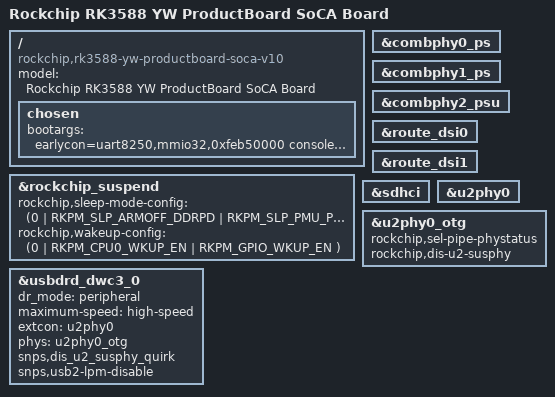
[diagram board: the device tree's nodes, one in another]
// SPDX-License-Identifier: (GPL-2.0+ OR MIT)
/*
 * Copyright (c) 2025 Rockchip Electronics Co., Ltd.
 *
 */

/dts-v1/;

#include "dt-bindings/usb/pd.h"
#include "rk3588m.dtsi"
#include "rk3588-yw-v10.dtsi"
#include "rk3588-rk806-dual.dtsi"
#include "rk3588-android.dtsi"
//#include "rk3588-yw-v10-soca-audio.dtsi"
//#include "rk3588-yw-fastboard-maxim-max96712-dphy0.dtsi"

/ {
	model = "Rockchip RK3588 YW ProductBoard SoCA Board";
	compatible = "rockchip,rk3588-yw-productboard-soca-v10", "rockchip,rk3588";

	chosen: chosen {
		bootargs = "earlycon=uart8250,mmio32,0xfeb50000 console=ttyFIQ0 irqchip.gicv3_pseudo_nmi=0 rcupdate.rcu_expedited=1 rcu_nocbs=all spidev.bufsiz=131072 default_hugepagesz=32M hugepagesz=32M hugepages=16";
	};
};

&combphy0_ps {
	status = "okay";
};

&combphy1_ps {
	status = "okay";
};

&combphy2_psu {
	status = "okay";
};

#if 0
&gmac0 {
	/* Use rgmii-rxid mode to disable rx delay inside Soc */
	phy-mode = "rgmii-rxid";
	clock_in_out = "output";
	snps,reset-gpio = <&gpio3 RK_PB7 GPIO_ACTIVE_LOW>;
	snps,reset-active-low;
	/* Reset time is 20ms, 100ms for rtl8211f */
	snps,reset-delays-us = <0 20000 100000>;
	pinctrl-names = "default";
	pinctrl-0 = <&gmac0_miim
		     &gmac0_tx_bus2
		     &gmac0_rx_bus2
		     &gmac0_rgmii_clk
		     &gmac0_rgmii_bus
		     &phydisb>;
	tx_delay = <0x20>;
	phy-handle = <&rgmii_phy>;
	status = "okay";
};

&i2s0_8ch {
	status = "okay";
	pinctrl-0 = <&i2s0_lrck
		     &i2s0_sclk
		     &i2s0_sdi0
		     &i2s0_sdo0>;
};

&mdio0 {
	rgmii_phy: phy@1 {
		compatible = "ethernet-phy-ieee802.3-c22";
		reg = <0x1>;
		motorcomm,vddio = "1v8";
	};
};
#endif

#if 0
&pcie30phy {
	rockchip,pcie30-phymode = <PHY_MODE_PCIE_AGGREGATION>;
	status = "okay";
};

&pcie3x4 {
	reset-gpios = <&gpio3 RK_PC6 GPIO_ACTIVE_HIGH>;
	//vpcie3v3-supply = <&vcc3v3_pcie30>;
	pinctrl-names = "default";
	pinctrl-0 = <&pcie20x1_0_clkreqn_m1>;
	status = "okay";
};

&pinctrl {
	gmac0 {
		phydisb: phydisb {
			rockchip,pins = <4 RK_PB5 RK_FUNC_GPIO &pcfg_output_high>;
		};
	};

/*
	vcc5v0-buck {
		vcc5v0_buck_en: vcc5v0-buck-en {
			rockchip,pins = <0 RK_PC2 RK_FUNC_GPIO &pcfg_pull_none>;
		};
	};
*/

	pcie {
		pcie20x1_0_clkreqn_m1: pcie20x1-0-clkreqn-m1 {
			rockchip,pins = <3 RK_PC4 RK_FUNC_GPIO &pcfg_output_low>;
		};
	};
};
#endif

&rockchip_suspend {
	rockchip,sleep-mode-config = <
		(0
		| RKPM_SLP_ARMOFF_DDRPD
		| RKPM_SLP_PMU_PMUALIVE_32K
		| RKPM_SLP_PMU_DIS_OSC
		| RKPM_SLP_32K_EXT
		)
	>;
	rockchip,wakeup-config = <
		(0
		| RKPM_CPU0_WKUP_EN
		| RKPM_GPIO_WKUP_EN
		)
	>;
	status = "okay";
};

&route_dsi0 {
	status = "okay";
};

&route_dsi1 {
	status = "okay";
};

&sdhci {
	/delete-property/ mmc-hs400-1_8v;
	/delete-property/ mmc-hs400-enhanced-strobe;
};

&u2phy0 {
	status = "okay";
};

&u2phy0_otg {
	//phy-supply = <&vcc5v0_host_usb20>;
	rockchip,sel-pipe-phystatus;
	rockchip,dis-u2-susphy;
	status = "okay";
};

/*
&u2phy2_host {
	phy-supply = <&vcc5v0_host_usb30>;
};
*/

&usbdrd_dwc3_0 {
	dr_mode = "peripheral";
	maximum-speed = "high-speed";
	extcon = <&u2phy0>;
	phys = <&u2phy0_otg>;
	phy-names = "usb2-phy";
	snps,dis_u2_susphy_quirk;
	snps,usb2-lpm-disable;
	status = "okay";
};
